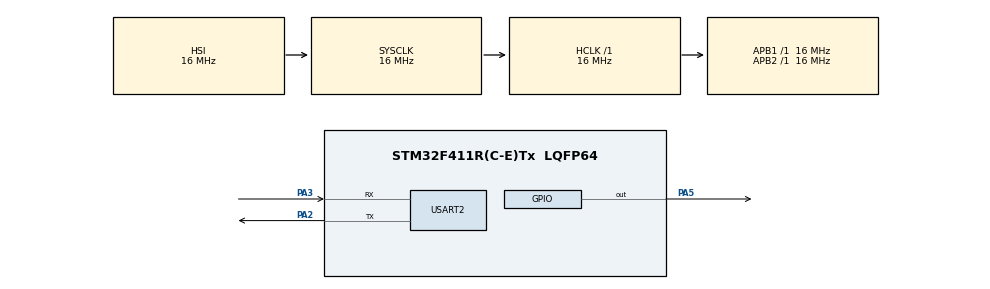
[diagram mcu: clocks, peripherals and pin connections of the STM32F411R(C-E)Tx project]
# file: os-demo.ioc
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FREERTOS.Tasks01=Task1,0,128,led_blink,Default,NULL,Dynamic,NULL,NULL;Task2,-3,128,echo_server,Default,NULL,Dynamic,NULL,NULL
Mcu.Family=STM32F4
Mcu.Name=STM32F411R(C-E)Tx
Mcu.Package=LQFP64
NVIC.PriorityGroup=NVIC_PRIORITYGROUP_4
PA2.Mode=Asynchronous
PA2.Signal=USART2_TX
PA3.Mode=Asynchronous
PA3.Signal=USART2_RX
PA5.Signal=GPIO_Output
ProjectManager.HeapSize=0x200
ProjectManager.StackSize=0x400
ProjectManager.TargetToolchain=Makefile
RCC.AHBFreq_Value=16000000
RCC.APB1Freq_Value=16000000
RCC.APB2Freq_Value=16000000
RCC.CortexFreq_Value=16000000
RCC.HSE_VALUE=25000000
RCC.HSI_VALUE=16000000
RCC.LSE_VALUE=32768
RCC.SYSCLKFreq_VALUE=16000000
RCC.VCOOutputFreq_Value=192000000
USART2.VirtualMode=VM_ASYNC
VP_FREERTOS_VS_CMSIS_V1.Mode=CMSIS_V1
board=custom

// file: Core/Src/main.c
/* USER CODE BEGIN Header */
/**
  ******************************************************************************
  * @file           : main.c
  * @brief          : Main program body
  ******************************************************************************
  * @attention
  *
  * <h2><center>&copy; Copyright (c) 2021 STMicroelectronics.
  * All rights reserved.</center></h2>
  *
  * This software component is licensed by ST under BSD 3-Clause license,
  * the "License"; You may not use this file except in compliance with the
  * License. You may obtain a copy of the License at:
  *                        opensource.org/licenses/BSD-3-Clause
  *
  ******************************************************************************
  */
/* USER CODE END Header */
#include "main.h"
#include "cmsis_os.h"

UART_HandleTypeDef huart2;

osThreadId Task1Handle;
osThreadId Task2Handle;

void SystemClock_Config(void);
static void MX_GPIO_Init(void);
static void MX_USART2_UART_Init(void);
void led_blink(void const * argument);
void echo_server(void const * argument);

int main(void)
{

  /* MCU Configuration--------------------------------------------------------*/

  /* Reset of all peripherals, Initializes the Flash interface and the Systick. */
  HAL_Init();

  /* Configure the system clock */
  SystemClock_Config();

  /* Initialize all configured peripherals */
  MX_GPIO_Init();
  MX_USART2_UART_Init();

  /* Create the thread(s) */
  /* definition and creation of Task1 */
  osThreadDef(Task1, led_blink, osPriorityNormal, 0, 128);
  Task1Handle = osThreadCreate(osThread(Task1), NULL);

  /* definition and creation of Task2 */
  osThreadDef(Task2, echo_server, osPriorityNormal, 0, 128);
  Task2Handle = osThreadCreate(osThread(Task2), NULL);

  /* Start scheduler */
  osKernelStart();

  /* We should never get here as control is now taken by the scheduler */
  /* Infinite loop */
  while (1)
  {

  }
}

void SystemClock_Config(void)
{
  RCC_OscInitTypeDef RCC_OscInitStruct = {0};
  RCC_ClkInitTypeDef RCC_ClkInitStruct = {0};

  /** Configure the main internal regulator output voltage
  */
  __HAL_RCC_PWR_CLK_ENABLE();
  __HAL_PWR_VOLTAGESCALING_CONFIG(PWR_REGULATOR_VOLTAGE_SCALE1);
  /** Initializes the RCC Oscillators according to the specified parameters
  * in the RCC_OscInitTypeDef structure.
  */
  RCC_OscInitStruct.OscillatorType = RCC_OSCILLATORTYPE_HSI;
  RCC_OscInitStruct.HSIState = RCC_HSI_ON;
  RCC_OscInitStruct.HSICalibrationValue = RCC_HSICALIBRATION_DEFAULT;
  RCC_OscInitStruct.PLL.PLLState = RCC_PLL_NONE;
  if (HAL_RCC_OscConfig(&RCC_OscInitStruct) != HAL_OK)
  {
    Error_Handler();
  }
  /** Initializes the CPU, AHB and APB buses clocks
  */
  RCC_ClkInitStruct.ClockType = RCC_CLOCKTYPE_HCLK|RCC_CLOCKTYPE_SYSCLK
                              |RCC_CLOCKTYPE_PCLK1|RCC_CLOCKTYPE_PCLK2;
  RCC_ClkInitStruct.SYSCLKSource = RCC_SYSCLKSOURCE_HSI;
  RCC_ClkInitStruct.AHBCLKDivider = RCC_SYSCLK_DIV1;
  RCC_ClkInitStruct.APB1CLKDivider = RCC_HCLK_DIV1;
  RCC_ClkInitStruct.APB2CLKDivider = RCC_HCLK_DIV1;

  if (HAL_RCC_ClockConfig(&RCC_ClkInitStruct, FLASH_LATENCY_0) != HAL_OK)
  {
    Error_Handler();
  }
}

static void MX_USART2_UART_Init(void)
{

  huart2.Instance = USART2;
  huart2.Init.BaudRate = 115200;
  huart2.Init.WordLength = UART_WORDLENGTH_8B;
  huart2.Init.StopBits = UART_STOPBITS_1;
  huart2.Init.Parity = UART_PARITY_NONE;
  huart2.Init.Mode = UART_MODE_TX_RX;
  huart2.Init.HwFlowCtl = UART_HWCONTROL_NONE;
  huart2.Init.OverSampling = UART_OVERSAMPLING_16;
  if (HAL_UART_Init(&huart2) != HAL_OK)
  {
    Error_Handler();
  }

}

static void MX_GPIO_Init(void)
{
  GPIO_InitTypeDef GPIO_InitStruct = {0};

  /* GPIO Ports Clock Enable */
  __HAL_RCC_GPIOA_CLK_ENABLE();

  /*Configure GPIO pin Output Level */
  HAL_GPIO_WritePin(GPIOA, GPIO_PIN_5, GPIO_PIN_RESET);

  /*Configure GPIO pin : PA5 */
  GPIO_InitStruct.Pin = GPIO_PIN_5;
  GPIO_InitStruct.Mode = GPIO_MODE_OUTPUT_PP;
  GPIO_InitStruct.Pull = GPIO_NOPULL;
  GPIO_InitStruct.Speed = GPIO_SPEED_FREQ_LOW;
  HAL_GPIO_Init(GPIOA, &GPIO_InitStruct);

}

void led_blink(void const * argument)
{
  /* USER CODE BEGIN 5 */
  /* Infinite loop */
  for(;;)
  {
    HAL_GPIO_WritePin(GPIOA, GPIO_PIN_5, GPIO_PIN_SET);
    osDelay(1);
    HAL_GPIO_WritePin(GPIOA, GPIO_PIN_5, GPIO_PIN_RESET);
    osDelay(1);
  }
  /* USER CODE END 5 */
}

void echo_server(void const * argument)
{
  /* USER CODE BEGIN echo_server */
  /* Infinite loop */
  for(;;)
  {
    HAL_UART_Transmit(&huart2, "Free RTOS\n", 10, 100);
  }
  /* USER CODE END echo_server */
}

void Error_Handler(void)
{
  __disable_irq();
  while (1)
  {
  }
}

/************************ (C) COPYRIGHT STMicroelectronics *****END OF FILE****/
